# SIMG301M104LGL register map
Vendor: Silicon Labs; Series: Si; File version: B
Registers are 32-bit, read-write, reset 0x0 unless marked. A register's access mark holds for its fields unless they carry their own. Offsets are from the block's base; [hi:lo] are bit positions; {n}, {i} and the like mark numbered series.

## RPA_NS — RPA_NS Registers
Base 0x40898000
Same registers: RPA_S 0x50898000
0x00 IPVERSION ro reset 0x1
  [31:0] IPVERSION — IP version ID
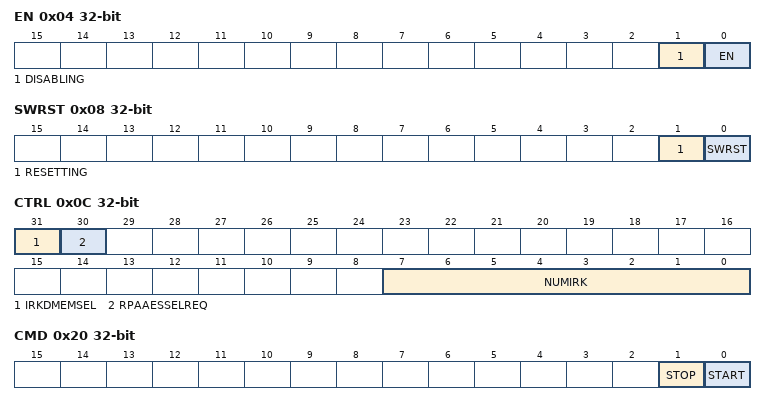
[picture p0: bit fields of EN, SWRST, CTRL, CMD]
0x04 EN
  [1] DISABLING ro — Disablement busy status
  [0] EN — Module enable
0x08 SWRST
  [1] RESETTING ro — Software reset command
  [0] SWRST wo — Status of reset
0x0C CTRL
  [31] IRKDMEMSEL — Selects DMEM IRKs
  [30] RPAAESSELREQ — Preemption request
  [7:0] NUMIRK — Number of IRKs
0x10 PRAND
  [23:0] PRAND
0x14 HASH
  [23:0] HASH
0x18 IRKADDR
  [31:0] IRKADDR — IRK address
0x1C IRKKEYSLOTID
  [7:0] IRKKEYSLOTID
0x20 CMD wo
  [1] STOP — Stop RPA
  [0] START — Start RPA
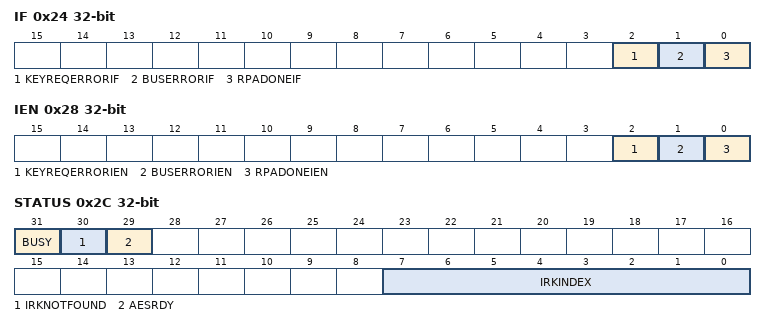
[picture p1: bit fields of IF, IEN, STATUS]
0x24 IF
  [2] KEYREQERRORIF — Key request error IF
  [1] BUSERRORIF
  [0] RPADONEIF
0x28 IEN
  [2] KEYREQERRORIEN — Enable key request error IF
  [1] BUSERRORIEN — Enable bus error IF
  [0] RPADONEIEN — Enable RPA done IF
0x2C STATUS ro
  [31] BUSY — RPA busy
  [30] IRKNOTFOUND
  [29] AESRDY — AES ready
  [7:0] IRKINDEX
0x80 IRKMASK0 reset 0xFFFFFFFF
  [31:0] IRKMASK — IRK masks

## SCRATCHPAD_NS — SCRATCHPAD_NS Registers
Base 0xA3004000
Same registers: SCRATCHPAD_S 0xB3004000
0x00 SREG0 — Used for SIMCTRL Pointer in Verification Environment
  [31:0] SCRATCH — Scratch Pad Register
0x04 SREG1 — Used for SIMCTRL Data Access in Verification Environment
  [31:0] SCRATCH

## SEMAILBOX_NS_HOST — SEMAILBOX_NS_HOST Registers
Base 0x42800000
Same registers: SEMAILBOX_S_HOST 0x52800000
0x00 FIFO — A write access to any address in this area will be mapped to the TX FIFO (only for the payload). A read access to any address in this area will be mapped to the RX FIFO (only for the payload). Using an address range (16 x 32-bit) rather than one single address mapped to the FIFO allows using incremental bursts.
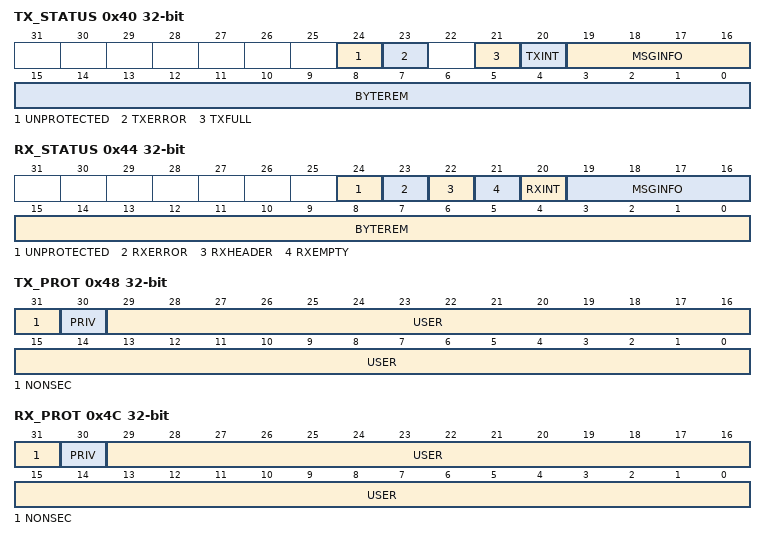
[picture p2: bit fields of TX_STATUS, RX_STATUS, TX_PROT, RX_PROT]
0x40 TX_STATUS ro
  [24] UNPROTECTED, [23] TXERROR, [21] TXFULL, [20] TXINT, [19:16] MSGINFO, [15:0] BYTEREM
0x44 RX_STATUS ro
  [24] UNPROTECTED, [23] RXERROR, [22] RXHEADER, [21] RXEMPTY, [20] RXINT, [19:16] MSGINFO, [15:0] BYTEREM
0x48 TX_PROT ro — TX Protection register.
  [31] NONSEC, [30] PRIV, [29:0] USER
0x4C RX_PROT ro — RX Protection register.
  [31] NONSEC, [30] PRIV, [29:0] USER
0x50 TX_HEADER wo — A write access to this register will be mapped to the TX FIFO (only for header).
  [31:0] TXHEADER
0x54 RX_HEADER ro — A read access to this register will be mapped to the RX FIFO (only for the header).
  [31:0] RXHEADER
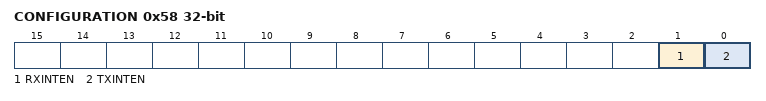
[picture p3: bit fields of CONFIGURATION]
0x58 CONFIGURATION
  [1] RXINTEN, [0] TXINTEN

## SEMAPHORE0_NS — SEMAPHORE0_NS Registers
Base 0x4082C000
Same registers: SEMAPHORE1_NS 0x40830000, SEMAPHORE0_S 0x5082C000, SEMAPHORE1_S 0x50830000
0x00 IPVERSION ro reset 0x1
  [31:0] IPVERSION — IP version ID
{0x4+4i} LOCK{i} (i=0..127)
  [0] LOCK{i} — SEMAPHORE LOCK {i} Bit Register

## SEPORTAL_NS — SEPORTAL_NS Registers
Base 0xA3010000
Same registers: SEPORTAL_S 0xB3010000
0x10 IPID ro reset 0x1
  [31:0] IPVERSION — IP version ID
0x14 CTRL
  [0] LPW0PWRUPREQ — LPW0 Power Up Request
0x18 STATUS
  [0] LPW0PWRUPACK — LPW0 Power up status

## SOCPLL0_NS — SOCPLL0_NS Registers
Base 0x40800000
Same registers: SOCPLL0_S 0x50800000
0x00 IPVERSION ro reset 0x2
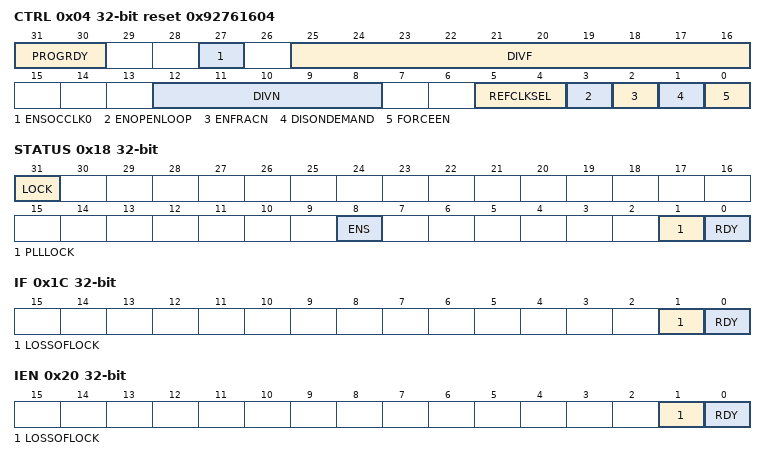
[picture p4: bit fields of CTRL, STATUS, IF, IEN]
0x04 CTRL reset 0x92761604
  [31:30] PROGRDY — Programmable RDY delay
    0=RDY_DELAY_0US (0us delay for rdy generation); 1=RDY_DELAY_4US (4us delay for rdy generation); 2=RDY_DELAY_8US (8us delay for rdy generation); 3=RDY_DELAY_16US (16us delay for rdy generation)
  [27] ENSOCCLK0 — Enable flash phy clock
  [25:16] DIVF — Fractional divider value
  [12:8] DIVN — Integer divider value
  [5:4] REFCLKSEL — Refrence clock source selection
    0=REF_HFXO (Select HFXO as reference clock); 1=REF_HFRCO (Select HFRCO as reference clock); 2=REF_EXTCLK (Select external clock as reference clock)
  [3] ENOPENLOOP — Open loop mode enable
  [2] ENFRACN — Frac-N Mode Enable
  [1] DISONDEMAND — Disable on Demand
  [0] FORCEEN — Force Enable
0x18 STATUS ro
  [31] LOCK — Lock Status
    0=UNLOCKED (SOCPLL is unlocked); 1=LOCKED (SOCPLL is locked)
  [8] ENS — SOCPLL Enable
  [1] PLLLOCK — Goes high within TDC range
  [0] RDY — SOCPLL Ready
0x1C IF
  [1] LOSSOFLOCK — Loss of PLL Lock Flag
  [0] RDY — Ready Interrupt Flag
0x20 IEN
  [1] LOSSOFLOCK — LOSSOFLOCK Interrupt Enable
  [0] RDY — RDY Interrupt Enable
0x24 LOCK wo reset 0x81A6
  [15:0] LOCKKEY — Configuration Lock Key
    0x81A6=UNLOCK (Write this value to unlock)
